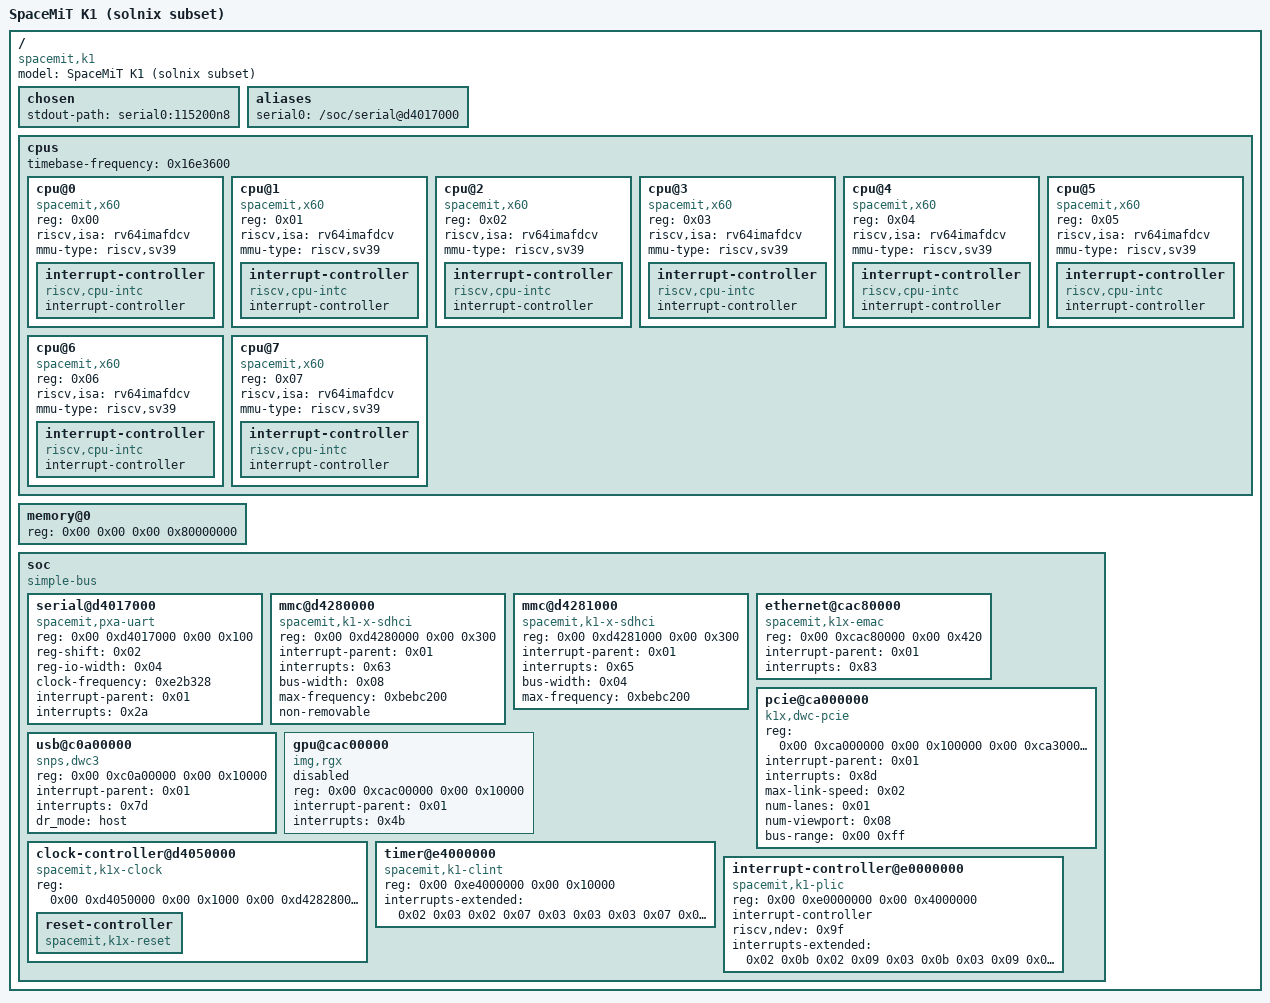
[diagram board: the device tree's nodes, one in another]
/dts-v1/;

/ {
	#address-cells = <0x02>;
	#size-cells = <0x02>;
	model = "SpaceMiT K1 (solnix subset)";
	compatible = "spacemit,k1";

	chosen {
		stdout-path = "serial0:115200n8";
	};

	aliases {
		serial0 = "/soc/serial@d4017000";
	};

	cpus {
		#address-cells = <0x01>;
		#size-cells = <0x00>;
		timebase-frequency = <0x16e3600>;

		cpu@0 {
			device_type = "cpu";
			reg = <0x00>;
			compatible = "spacemit,x60", "riscv";
			riscv,isa = "rv64imafdcv";
			mmu-type = "riscv,sv39";

			interrupt-controller {
				#interrupt-cells = <0x01>;
				compatible = "riscv,cpu-intc";
				interrupt-controller;
				phandle = <0x02>;
			};
		};

		cpu@1 {
			device_type = "cpu";
			reg = <0x01>;
			compatible = "spacemit,x60", "riscv";
			riscv,isa = "rv64imafdcv";
			mmu-type = "riscv,sv39";

			interrupt-controller {
				#interrupt-cells = <0x01>;
				compatible = "riscv,cpu-intc";
				interrupt-controller;
				phandle = <0x03>;
			};
		};

		cpu@2 {
			device_type = "cpu";
			reg = <0x02>;
			compatible = "spacemit,x60", "riscv";
			riscv,isa = "rv64imafdcv";
			mmu-type = "riscv,sv39";

			interrupt-controller {
				#interrupt-cells = <0x01>;
				compatible = "riscv,cpu-intc";
				interrupt-controller;
				phandle = <0x04>;
			};
		};

		cpu@3 {
			device_type = "cpu";
			reg = <0x03>;
			compatible = "spacemit,x60", "riscv";
			riscv,isa = "rv64imafdcv";
			mmu-type = "riscv,sv39";

			interrupt-controller {
				#interrupt-cells = <0x01>;
				compatible = "riscv,cpu-intc";
				interrupt-controller;
				phandle = <0x05>;
			};
		};

		cpu@4 {
			device_type = "cpu";
			reg = <0x04>;
			compatible = "spacemit,x60", "riscv";
			riscv,isa = "rv64imafdcv";
			mmu-type = "riscv,sv39";

			interrupt-controller {
				#interrupt-cells = <0x01>;
				compatible = "riscv,cpu-intc";
				interrupt-controller;
				phandle = <0x06>;
			};
		};

		cpu@5 {
			device_type = "cpu";
			reg = <0x05>;
			compatible = "spacemit,x60", "riscv";
			riscv,isa = "rv64imafdcv";
			mmu-type = "riscv,sv39";

			interrupt-controller {
				#interrupt-cells = <0x01>;
				compatible = "riscv,cpu-intc";
				interrupt-controller;
				phandle = <0x07>;
			};
		};

		cpu@6 {
			device_type = "cpu";
			reg = <0x06>;
			compatible = "spacemit,x60", "riscv";
			riscv,isa = "rv64imafdcv";
			mmu-type = "riscv,sv39";

			interrupt-controller {
				#interrupt-cells = <0x01>;
				compatible = "riscv,cpu-intc";
				interrupt-controller;
				phandle = <0x08>;
			};
		};

		cpu@7 {
			device_type = "cpu";
			reg = <0x07>;
			compatible = "spacemit,x60", "riscv";
			riscv,isa = "rv64imafdcv";
			mmu-type = "riscv,sv39";

			interrupt-controller {
				#interrupt-cells = <0x01>;
				compatible = "riscv,cpu-intc";
				interrupt-controller;
				phandle = <0x09>;
			};
		};
	};

	memory@0 {
		device_type = "memory";
		reg = <0x00 0x00 0x00 0x80000000>;
	};

	soc {
		#address-cells = <0x02>;
		#size-cells = <0x02>;
		compatible = "simple-bus";
		ranges;

		serial@d4017000 {
			compatible = "spacemit,pxa-uart", "spacemit,k1-uart", "intel,xscale-uart", "snps,dw-apb-uart";
			reg = <0x00 0xd4017000 0x00 0x100>;
			reg-shift = <0x02>;
			reg-io-width = <0x04>;
			clock-frequency = <0xe2b328>;
			interrupt-parent = <0x01>;
			interrupts = <0x2a>;
			status = "okay";
		};

		mmc@d4280000 {
			compatible = "spacemit,k1-x-sdhci";
			reg = <0x00 0xd4280000 0x00 0x300>;
			interrupt-parent = <0x01>;
			interrupts = <0x63>;
			bus-width = <0x08>;
			max-frequency = <0xbebc200>;
			non-removable;
			status = "okay";
		};

		mmc@d4281000 {
			compatible = "spacemit,k1-x-sdhci";
			reg = <0x00 0xd4281000 0x00 0x300>;
			interrupt-parent = <0x01>;
			interrupts = <0x65>;
			bus-width = <0x04>;
			max-frequency = <0xbebc200>;
			status = "okay";
		};

		ethernet@cac80000 {
			compatible = "spacemit,k1x-emac";
			reg = <0x00 0xcac80000 0x00 0x420>;
			interrupt-parent = <0x01>;
			interrupts = <0x83>;
			status = "okay";
		};

		pcie@ca000000 {
			compatible = "k1x,dwc-pcie";
			reg = <0x00 0xca000000 0x00 0x100000 0x00 0xca300000 0x00 0x10000 0x00 0x8f000000 0x00 0x100000>;
			reg-names = "dbi", "atu", "config";
			interrupt-parent = <0x01>;
			interrupts = <0x8d>;
			max-link-speed = <0x02>;
			num-lanes = <0x01>;
			num-viewport = <0x08>;
			device_type = "pci";
			#address-cells = <0x03>;
			#size-cells = <0x02>;
			bus-range = <0x00 0xff>;
			ranges = <0x2000000 0x00 0x90000000 0x00 0x90000000 0x00 0x8000000>;
			status = "okay";
		};

		usb@c0a00000 {
			compatible = "snps,dwc3";
			reg = <0x00 0xc0a00000 0x00 0x10000>;
			interrupt-parent = <0x01>;
			interrupts = <0x7d>;
			dr_mode = "host";
			status = "okay";
		};

		gpu@cac00000 {
			compatible = "img,rgx";
			reg = <0x00 0xcac00000 0x00 0x10000>;
			interrupt-parent = <0x01>;
			interrupts = <0x4b>;
			status = "disabled";
		};

		clock-controller@d4050000 {
			compatible = "spacemit,k1x-clock";
			reg = <0x00 0xd4050000 0x00 0x1000 0x00 0xd4282800 0x00 0x400 0x00 0xd4015000 0x00 0x1000 0x00 0xd4090000 0x00 0x1000>;
			reg-names = "ccu", "apmu", "apbc", "apbs";
			#clock-cells = <0x01>;
			status = "okay";

			reset-controller {
				compatible = "spacemit,k1x-reset";
				#reset-cells = <0x01>;
				status = "okay";
			};
		};

		timer@e4000000 {
			compatible = "spacemit,k1-clint", "riscv,clint0";
			reg = <0x00 0xe4000000 0x00 0x10000>;
			interrupts-extended = <0x02 0x03 0x02 0x07 0x03 0x03 0x03 0x07 0x04 0x03 0x04 0x07 0x05 0x03 0x05 0x07 0x06 0x03 0x06 0x07 0x07 0x03 0x07 0x07 0x08 0x03 0x08 0x07 0x09 0x03 0x09 0x07>;
		};

		interrupt-controller@e0000000 {
			compatible = "spacemit,k1-plic", "riscv,plic0";
			reg = <0x00 0xe0000000 0x00 0x4000000>;
			interrupt-controller;
			#interrupt-cells = <0x01>;
			#address-cells = <0x00>;
			riscv,ndev = <0x9f>;
			interrupts-extended = <0x02 0x0b 0x02 0x09 0x03 0x0b 0x03 0x09 0x04 0x0b 0x04 0x09 0x05 0x0b 0x05 0x09 0x06 0x0b 0x06 0x09 0x07 0x0b 0x07 0x09 0x08 0x0b 0x08 0x09 0x09 0x0b 0x09 0x09>;
			phandle = <0x01>;
		};
	};
};
